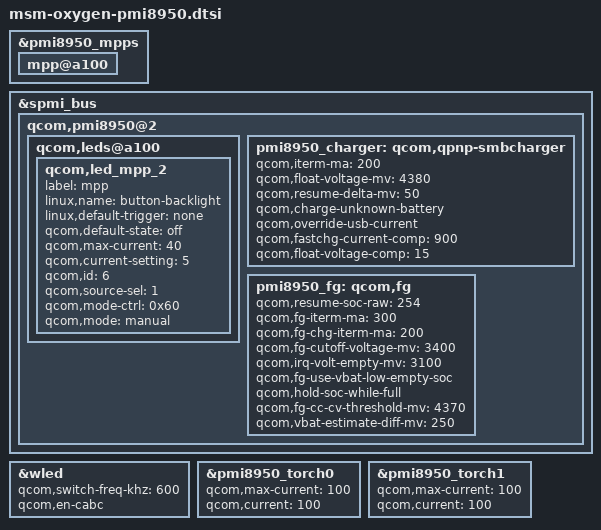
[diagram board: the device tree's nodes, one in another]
/*
 * Copyright (c) 2015-2018, The Linux Foundation. All rights reserved.
 *
 * This program is free software; you can redistribute it and/or modify
 * it under the terms of the GNU General Public License version 2 and
 * only version 2 as published by the Free Software Foundation.
 *
 * This program is distributed in the hope that it will be useful,
 * but WITHOUT ANY WARRANTY; without even the implied warranty of
 * MERCHANTABILITY or FITNESS FOR A PARTICULAR PURPOSE.  See the
 * GNU General Public License for more details.
 */

&pmi8950_mpps {
    mpp@a100 {
        status = "okay";
    };
};

&spmi_bus {
	qcom,pmi8950@2 {
	        qcom,leds@a100 {
			qcom,led_mpp_2 {
				label = "mpp";
				linux,name = "button-backlight";
				linux,default-trigger = "none";
				qcom,default-state = "off";
				qcom,max-current = <40>;
				qcom,current-setting = <5>;
				qcom,id = <6>;
				qcom,source-sel = <1>;
				qcom,mode-ctrl = <0x60>;
				qcom,mode = "manual";
			};
		};

		pmi8950_charger: qcom,qpnp-smbcharger {
			qcom,iterm-ma = <200>;
			qcom,float-voltage-mv = <4380>;
			qcom,resume-delta-mv = <50>;
			qcom,charge-unknown-battery;
			/delete-property/ qcom,autoadjust-vfloat;
			qcom,override-usb-current;
			qcom,fastchg-current-comp = <900>;
			qcom,float-voltage-comp = <15>;

		};

		pmi8950_fg: qcom,fg {
			/delete-property/ qcom,resume-soc;
			qcom,resume-soc-raw = <254>;
			qcom,fg-iterm-ma = <300>;
			qcom,fg-chg-iterm-ma = <200>;
			qcom,fg-cutoff-voltage-mv = <3400>;
			qcom,irq-volt-empty-mv = <3100>;
			qcom,fg-use-vbat-low-empty-soc;
			qcom,hold-soc-while-full;
			qcom,fg-cc-cv-threshold-mv =<4370>;
			qcom,vbat-estimate-diff-mv = <250>;

		};
	};
};

&wled {
    qcom,switch-freq-khz = <600>;
    /delete-property/ qcom,en-ext-pfet-sc-pro;
    qcom,en-cabc;
};

&pmi8950_charger {
    /delete-property/ qcom,autoadjust-vfloat;
};

&pmi8950_torch0 {
    qcom,max-current = <100>;
    qcom,current = <100>;
};

&pmi8950_torch1 {
    qcom,max-current = <100>;
    qcom,current = <100>;
};
